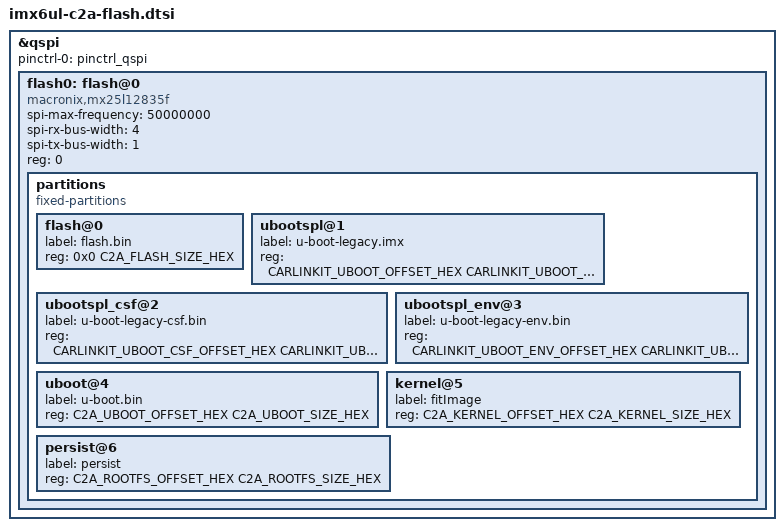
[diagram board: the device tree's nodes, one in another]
&qspi {
	pinctrl-names = "default";
	pinctrl-0 = <&pinctrl_qspi>;
	status = "okay";

	flash0: flash@0 {
		#address-cells = <1>;
		#size-cells = <1>;
		compatible = "macronix,mx25l12835f", "jedec,spi-nor";
		spi-max-frequency = <50000000>; /* possibly up to 60 */
		spi-rx-bus-width = <4>;          // QSPI
		spi-tx-bus-width = <1>;
		reg = <0>;

		partitions {
			compatible = "fixed-partitions";
			#address-cells = <1>;
			#size-cells = <1>;

						
			flash@0 {
				label = "flash.bin";
				reg = <0x0 C2A_FLASH_SIZE_HEX>;
			};

			ubootspl@1 {
				label = "u-boot-legacy.imx";
				reg = <CARLINKIT_UBOOT_OFFSET_HEX CARLINKIT_UBOOT_SIZE_HEX>;
			};

			ubootspl_csf@2 {
				label = "u-boot-legacy-csf.bin";
				reg = <CARLINKIT_UBOOT_CSF_OFFSET_HEX CARLINKIT_UBOOT_CSF_SIZE_HEX>;
			};

			ubootspl_env@3 {
				label = "u-boot-legacy-env.bin";
				reg = <CARLINKIT_UBOOT_ENV_OFFSET_HEX CARLINKIT_UBOOT_ENV_SIZE_HEX>;
			};

			uboot@4 {
				label = "u-boot.bin";
				reg = <C2A_UBOOT_OFFSET_HEX C2A_UBOOT_SIZE_HEX>;
			};

			kernel@5 {
				label = "fitImage";
				reg = <C2A_KERNEL_OFFSET_HEX C2A_KERNEL_SIZE_HEX>;
			};

			persist@6 {
				label = "persist";
				reg = <C2A_ROOTFS_OFFSET_HEX C2A_ROOTFS_SIZE_HEX>;
			};
        };
	};
};
